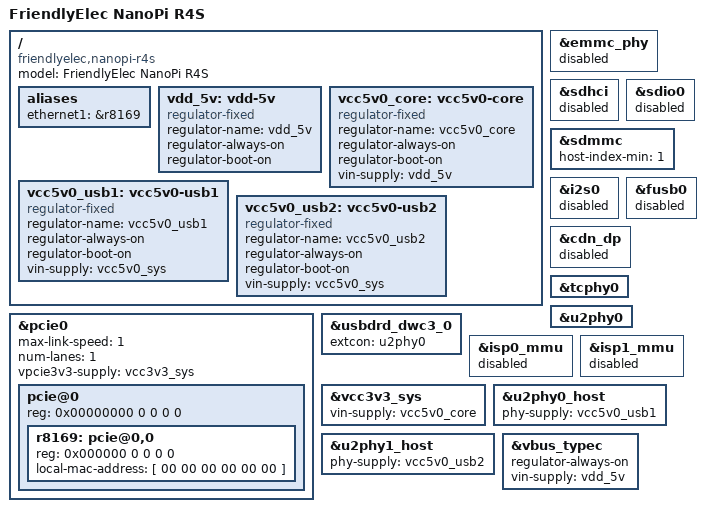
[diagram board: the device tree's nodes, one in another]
// SPDX-License-Identifier: (GPL-2.0+ OR MIT)
/*
 * Copyright (c) 2020 FriendlyElec Computer Tech. Co., Ltd.
 * (http://www.friendlyarm.com)
 */

/dts-v1/;
#include "rk3399-nanopi4.dtsi"

/ {
	model = "FriendlyElec NanoPi R4S";
	compatible = "friendlyelec,nanopi-r4s", "rockchip,rk3399";

	aliases {
		ethernet1 = &r8169;
	};
	vdd_5v: vdd-5v {
		compatible = "regulator-fixed";
		regulator-name = "vdd_5v";
		regulator-always-on;
		regulator-boot-on;
	};

	vcc5v0_core: vcc5v0-core {
		compatible = "regulator-fixed";
		regulator-name = "vcc5v0_core";
		regulator-always-on;
		regulator-boot-on;
		vin-supply = <&vdd_5v>;
	};

	vcc5v0_usb1: vcc5v0-usb1 {
		compatible = "regulator-fixed";
		regulator-name = "vcc5v0_usb1";
		regulator-always-on;
		regulator-boot-on;
		vin-supply = <&vcc5v0_sys>;
	};

	vcc5v0_usb2: vcc5v0-usb2 {
		compatible = "regulator-fixed";
		regulator-name = "vcc5v0_usb2";
		regulator-always-on;
		regulator-boot-on;
		vin-supply = <&vcc5v0_sys>;
	};
};

&emmc_phy {
	status = "disabled";
};

&sdhci {
	status = "disabled";
};

&sdio0 {
	status = "disabled";
};

&sdmmc {
	host-index-min = <1>;
};

&i2s0 {
	status = "disabled";
};

&pcie0 {
	max-link-speed = <1>;
	num-lanes = <1>;
	vpcie3v3-supply = <&vcc3v3_sys>;

	pcie@0 {
		reg = <0x00000000 0 0 0 0>;
		#address-cells = <3>;
		#size-cells = <2>;

		r8169: pcie@0,0 {
			reg = <0x000000 0 0 0 0>;
			local-mac-address = [ 00 00 00 00 00 00 ];
		};
	};
};

&fusb0 {
	status = "disabled";
};

&cdn_dp {
	/delete-property/ extcon;
	status = "disabled";
};

&tcphy0 {
	/delete-property/ extcon;
};

&u2phy0 {
	/delete-property/ extcon;
};

&usbdrd_dwc3_0 {
	/delete-property/ extcon;
	extcon = <&u2phy0>;
};

&isp0_mmu {
	status = "disabled";
};

&isp1_mmu {
	status = "disabled";
};

&vcc3v3_sys {
	vin-supply = <&vcc5v0_core>;
};

&u2phy0_host {
	phy-supply = <&vcc5v0_usb1>;
};

&u2phy1_host {
	phy-supply = <&vcc5v0_usb2>;
};

&vbus_typec {
	regulator-always-on;
	vin-supply = <&vdd_5v>;
};
